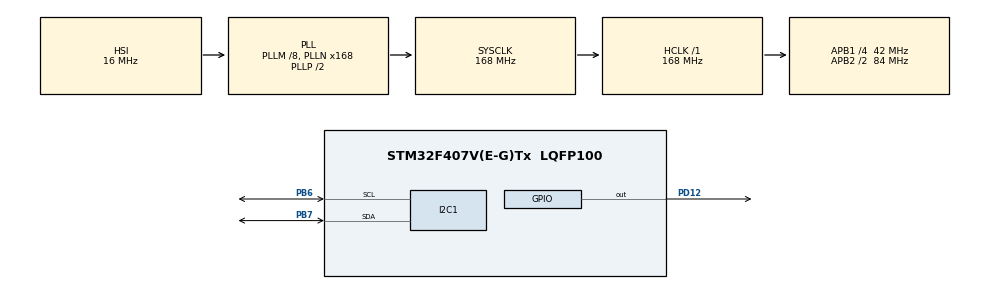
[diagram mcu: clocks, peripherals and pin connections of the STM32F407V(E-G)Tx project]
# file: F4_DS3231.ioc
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I2C1.I2C_Mode=I2C_Standard
Mcu.Family=STM32F4
Mcu.Name=STM32F407V(E-G)Tx
Mcu.Package=LQFP100
NVIC.I2C1_ER_IRQn=true\:1\:0\:true\:false\:true\:true\:true\:true
NVIC.I2C1_EV_IRQn=true\:1\:0\:true\:false\:true\:true\:true\:true
NVIC.PriorityGroup=NVIC_PRIORITYGROUP_4
PA13.Mode=Trace_Asynchronous_SW
PA13.Signal=SYS_JTMS-SWDIO
PA14.Mode=Trace_Asynchronous_SW
PA14.Signal=SYS_JTCK-SWCLK
PB3.Mode=Trace_Asynchronous_SW
PB3.Signal=SYS_JTDO-SWO
PB6.Mode=I2C
PB6.Signal=I2C1_SCL
PB7.Mode=I2C
PB7.Signal=I2C1_SDA
PD12.GPIO_PuPd=GPIO_PULLUP
PD12.GPIO_Speed=GPIO_SPEED_FREQ_HIGH
PD12.Signal=GPIO_Output
PH0-OSC_IN.Mode=HSE-External-Oscillator
PH0-OSC_IN.Signal=RCC_OSC_IN
PH1-OSC_OUT.Mode=HSE-External-Oscillator
PH1-OSC_OUT.Signal=RCC_OSC_OUT
ProjectManager.HeapSize=0x200
ProjectManager.StackSize=0x400
ProjectManager.TargetToolchain=STM32CubeIDE
RCC.48MHZClocksFreq_Value=84000000
RCC.AHBFreq_Value=168000000
RCC.APB1CLKDivider=RCC_HCLK_DIV4
RCC.APB1Freq_Value=42000000
RCC.APB1TimFreq_Value=84000000
RCC.APB2CLKDivider=RCC_HCLK_DIV2
RCC.APB2Freq_Value=84000000
RCC.APB2TimFreq_Value=168000000
RCC.CortexFreq_Value=168000000
RCC.HCLKFreq_Value=168000000
RCC.HSE_VALUE=25000000
RCC.HSI_VALUE=16000000
RCC.LSE_VALUE=32768
RCC.PLLM=8
RCC.PLLN=168
RCC.SYSCLKFreq_VALUE=168000000
RCC.SYSCLKSource=RCC_SYSCLKSOURCE_PLLCLK
RCC.VCOOutputFreq_Value=336000000
board=custom

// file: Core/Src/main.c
/* USER CODE BEGIN Header */
/**
  ******************************************************************************
  * @file           : main.c
  * @brief          : Main program body
  ******************************************************************************
  * @attention
  *
  * Copyright (c) 2023 STMicroelectronics.
  * All rights reserved.
  *
  * This software is licensed under terms that can be found in the LICENSE file
  * in the root directory of this software component.
  * If no LICENSE file comes with this software, it is provided AS-IS.
  *
  ******************************************************************************
  */
/* USER CODE END Header */
#include "main.h"

/* USER CODE BEGIN PTD */
typedef struct
{
	uint8_t gio;
	uint8_t phut;
	uint8_t giay;

	uint8_t thu;
	uint8_t ngay;
	uint8_t thang;
	uint8_t nam;
}DS3231_typedef;
/* USER CODE END PTD */

/* USER CODE BEGIN PD */
#define DS3231_ADD 0x68<<1
/* USER CODE END PD */

I2C_HandleTypeDef hi2c1;

/* USER CODE BEGIN PV */
DS3231_typedef TimeNow;
uint8_t Rece_Buffer[7];
uint8_t Tran_Buffer[7];
/* USER CODE END PV */

void SystemClock_Config(void);
static void MX_GPIO_Init(void);
static void MX_I2C1_Init(void);
/* USER CODE BEGIN PFP */
int _write(int file, char *ptr, int len);
/* USER CODE END PFP */

/* USER CODE BEGIN 0 */
uint8_t BCD2DEC(uint8_t data)
{
	return (data>>4)*10 + (data&0x0f);
}
uint8_t DEC2BCD(uint8_t data)
{
	return (data/10)<<4|(data%10);
}
void SetTime(uint8_t gio, uint8_t phut, uint8_t giay, uint8_t thu, uint8_t ngay, uint8_t thang, uint8_t nam)
{
	Tran_Buffer[0] = DEC2BCD(giay);
	Tran_Buffer[1] = DEC2BCD(phut);
	Tran_Buffer[2] = DEC2BCD(gio);

	Tran_Buffer[3] = DEC2BCD(thu);
	Tran_Buffer[4] = DEC2BCD(ngay);
	Tran_Buffer[5] = DEC2BCD(thang);
	Tran_Buffer[6] = DEC2BCD(nam);
	HAL_I2C_Mem_Write_IT(&hi2c1, DS3231_ADD, 0x00, I2C_MEMADD_SIZE_8BIT, Tran_Buffer, sizeof(Tran_Buffer));
}
void HAL_I2C_MemRxCpltCallback(I2C_HandleTypeDef *hi2c)
{
	UNUSED(hi2c);
	if(hi2c->Instance == I2C1)
	{
		TimeNow.giay = BCD2DEC(Rece_Buffer[0]);
		TimeNow.phut = BCD2DEC(Rece_Buffer[1]);
		TimeNow.gio = BCD2DEC(Rece_Buffer[2]);
		TimeNow.thu = BCD2DEC(Rece_Buffer[3]);
		TimeNow.ngay = BCD2DEC(Rece_Buffer[4]);
		TimeNow.thang = BCD2DEC(Rece_Buffer[5]);
		TimeNow.nam = BCD2DEC(Rece_Buffer[6]);
	}
}
void GetTime()
{
	HAL_I2C_Mem_Read_IT(&hi2c1, DS3231_ADD, 0x00, I2C_MEMADD_SIZE_8BIT, Rece_Buffer, sizeof(Rece_Buffer));
}
/* USER CODE END 0 */

int main(void)
{

  /* MCU Configuration--------------------------------------------------------*/

  /* Reset of all peripherals, Initializes the Flash interface and the Systick. */
  HAL_Init();

  /* Configure the system clock */
  SystemClock_Config();

  /* Initialize all configured peripherals */
  MX_GPIO_Init();
  MX_I2C1_Init();
  /* USER CODE BEGIN 2 */
//  SetTime(10, 35, 6, 5, 27, 4, 23);
  /* USER CODE END 2 */

  /* Infinite loop */
  while (1)
  {

    /* USER CODE BEGIN 3 */
	  GetTime();
	  printf("Gio: %d - phut: %d - giay: %d - ngay: %d - thang: %d - nam: %d\n",
			  TimeNow.gio,TimeNow.phut,TimeNow.giay,TimeNow.ngay,TimeNow.thang,TimeNow.nam+2000);

	  HAL_Delay(1000);
  }
  /* USER CODE END 3 */
}

void SystemClock_Config(void)
{
  RCC_OscInitTypeDef RCC_OscInitStruct = {0};
  RCC_ClkInitTypeDef RCC_ClkInitStruct = {0};

  /** Configure the main internal regulator output voltage
  */
  __HAL_RCC_PWR_CLK_ENABLE();
  __HAL_PWR_VOLTAGESCALING_CONFIG(PWR_REGULATOR_VOLTAGE_SCALE1);

  /** Initializes the RCC Oscillators according to the specified parameters
  * in the RCC_OscInitTypeDef structure.
  */
  RCC_OscInitStruct.OscillatorType = RCC_OSCILLATORTYPE_HSI;
  RCC_OscInitStruct.HSIState = RCC_HSI_ON;
  RCC_OscInitStruct.HSICalibrationValue = RCC_HSICALIBRATION_DEFAULT;
  RCC_OscInitStruct.PLL.PLLState = RCC_PLL_ON;
  RCC_OscInitStruct.PLL.PLLSource = RCC_PLLSOURCE_HSI;
  RCC_OscInitStruct.PLL.PLLM = 8;
  RCC_OscInitStruct.PLL.PLLN = 168;
  RCC_OscInitStruct.PLL.PLLP = RCC_PLLP_DIV2;
  RCC_OscInitStruct.PLL.PLLQ = 4;
  if (HAL_RCC_OscConfig(&RCC_OscInitStruct) != HAL_OK)
  {
    Error_Handler();
  }

  /** Initializes the CPU, AHB and APB buses clocks
  */
  RCC_ClkInitStruct.ClockType = RCC_CLOCKTYPE_HCLK|RCC_CLOCKTYPE_SYSCLK
                              |RCC_CLOCKTYPE_PCLK1|RCC_CLOCKTYPE_PCLK2;
  RCC_ClkInitStruct.SYSCLKSource = RCC_SYSCLKSOURCE_PLLCLK;
  RCC_ClkInitStruct.AHBCLKDivider = RCC_SYSCLK_DIV1;
  RCC_ClkInitStruct.APB1CLKDivider = RCC_HCLK_DIV4;
  RCC_ClkInitStruct.APB2CLKDivider = RCC_HCLK_DIV2;

  if (HAL_RCC_ClockConfig(&RCC_ClkInitStruct, FLASH_LATENCY_5) != HAL_OK)
  {
    Error_Handler();
  }
}

static void MX_I2C1_Init(void)
{

  hi2c1.Instance = I2C1;
  hi2c1.Init.ClockSpeed = 100000;
  hi2c1.Init.DutyCycle = I2C_DUTYCYCLE_2;
  hi2c1.Init.OwnAddress1 = 0;
  hi2c1.Init.AddressingMode = I2C_ADDRESSINGMODE_7BIT;
  hi2c1.Init.DualAddressMode = I2C_DUALADDRESS_DISABLE;
  hi2c1.Init.OwnAddress2 = 0;
  hi2c1.Init.GeneralCallMode = I2C_GENERALCALL_DISABLE;
  hi2c1.Init.NoStretchMode = I2C_NOSTRETCH_DISABLE;
  if (HAL_I2C_Init(&hi2c1) != HAL_OK)
  {
    Error_Handler();
  }

}

static void MX_GPIO_Init(void)
{
  GPIO_InitTypeDef GPIO_InitStruct = {0};

  /* GPIO Ports Clock Enable */
  __HAL_RCC_GPIOH_CLK_ENABLE();
  __HAL_RCC_GPIOD_CLK_ENABLE();
  __HAL_RCC_GPIOA_CLK_ENABLE();
  __HAL_RCC_GPIOB_CLK_ENABLE();

  /*Configure GPIO pin Output Level */
  HAL_GPIO_WritePin(GPIOD, GPIO_PIN_12, GPIO_PIN_RESET);

  /*Configure GPIO pin : PD12 */
  GPIO_InitStruct.Pin = GPIO_PIN_12;
  GPIO_InitStruct.Mode = GPIO_MODE_OUTPUT_PP;
  GPIO_InitStruct.Pull = GPIO_PULLUP;
  GPIO_InitStruct.Speed = GPIO_SPEED_FREQ_HIGH;
  HAL_GPIO_Init(GPIOD, &GPIO_InitStruct);

}

/* USER CODE BEGIN 4 */
int _write(int file, char *ptr, int len)
{
	int DataIdx;
    for(DataIdx = 0; DataIdx < len; DataIdx ++)
    { ITM_SendChar(*ptr++); }
     return len;
}
/* USER CODE END 4 */

void Error_Handler(void)
{
  __disable_irq();
  while (1)
  {
  }
}
